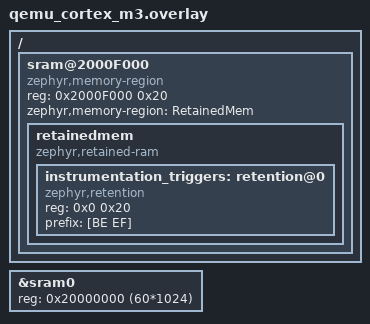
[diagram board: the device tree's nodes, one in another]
 /*
 * Copyright (c) 2025 Analog Devices, Inc.
 * Copyright (c) 2025 Antmicro <www.antmicro.com>
 *
 * SPDX-License-Identifier: Apache-2.0
 */

/ {
	sram@2000F000 {
		compatible = "zephyr,memory-region", "mmio-sram";
		reg = <0x2000F000 0x20>;
		zephyr,memory-region = "RetainedMem";
		status = "okay";

		retainedmem {
			compatible = "zephyr,retained-ram";
			status = "okay";
			#address-cells = <1>;
			#size-cells = <1>;

			instrumentation_triggers: retention@0 {
				compatible = "zephyr,retention";
				status = "okay";

				reg = <0x0 0x20>;

				prefix = [BE EF];
			};
                };
	};
};

&sram0 {
	reg = <0x20000000 (60*1024)>;
};
